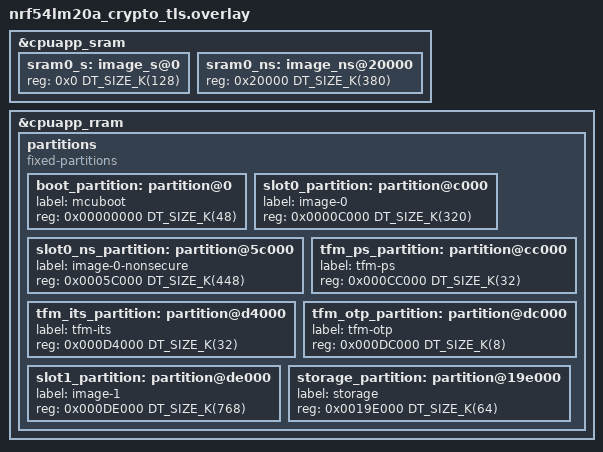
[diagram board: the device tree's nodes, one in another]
/*
 * Copyright (c) 2026 Nordic Semiconductor ASA
 *
 * SPDX-License-Identifier: LicenseRef-Nordic-5-Clause
 */

/*
 * Crypto/TLS-heavy TF-M partition layout for nRF54LM20A
 *
 * nRF54LM20A has 2036 kB of RRAM and 512 kB of SRAM (508 kB usable).
 * TrustZone flash region alignment: 4 kB (MPC-based)
 * TrustZone RAM region alignment:   4 kB
 * RRAM erase-block-size:            4 kB
 *
 * Optimized for TLS/DTLS-heavy applications:
 * - Enlarged PS (32 kB) for X.509 certificate chains
 * - Enlarged ITS (32 kB) for TLS session keys and PSKs
 * - Full TF-M crypto for TLS 1.2/1.3
 * - MCUboot for secure firmware updates
 * - Large NS application space
 *
 * Suitable for: cloud-connected devices, HTTPS clients, MQTT+TLS
 */

&cpuapp_sram {
	sram0_s: image_s@0 {
		#address-cells = <1>;
		#size-cells = <1>;
		reg = <0x0 DT_SIZE_K(128)>;
		ranges = <0x0 0x0 DT_SIZE_K(128)>;
	};

	sram0_ns: image_ns@20000 {
		#address-cells = <1>;
		#size-cells = <1>;
		reg = <0x20000 DT_SIZE_K(380)>;
		ranges = <0x0 0x20000 DT_SIZE_K(380)>;
	};
};

&cpuapp_rram {
	partitions {
		compatible = "fixed-partitions";
		#address-cells = <1>;
		#size-cells = <1>;

		/*
		 * Flash layout (all addresses 4 kB aligned):
		 *
		 * 0x00000000  MCUboot bootloader        (48 kB)
		 * 0x0000C000  Primary slot:
		 *   0x0000C000  TF-M secure image       (320 kB)
		 *   0x0005C000  Non-secure application   (448 kB)
		 * 0x000CC000  TF-M PS                    (32 kB)
		 *             (enlarged for X.509 certificate chains)
		 * 0x000D4000  TF-M ITS                   (32 kB)
		 *             (enlarged for TLS session keys, PSKs)
		 * 0x000DC000  TF-M OTP / NV counters      (8 kB)
		 * 0x000DE000  Secondary slot            (768 kB)
		 * 0x0019E000  Non-secure storage         (64 kB)
		 *
		 * Primary = 320 + 448 = 768 kB = Secondary
		 * Total: 48 + 768 + 32 + 32 + 8 + 768 + 64 = 1720 kB
		 */

		boot_partition: partition@0 {
			label = "mcuboot";
			reg = <0x00000000 DT_SIZE_K(48)>;
		};

		slot0_partition: partition@c000 {
			label = "image-0";
			reg = <0x0000C000 DT_SIZE_K(320)>;
		};

		slot0_ns_partition: partition@5c000 {
			label = "image-0-nonsecure";
			reg = <0x0005C000 DT_SIZE_K(448)>;
		};

		tfm_ps_partition: partition@cc000 {
			label = "tfm-ps";
			reg = <0x000CC000 DT_SIZE_K(32)>;
		};

		tfm_its_partition: partition@d4000 {
			label = "tfm-its";
			reg = <0x000D4000 DT_SIZE_K(32)>;
		};

		tfm_otp_partition: partition@dc000 {
			label = "tfm-otp";
			reg = <0x000DC000 DT_SIZE_K(8)>;
		};

		slot1_partition: partition@de000 {
			label = "image-1";
			reg = <0x000DE000 DT_SIZE_K(768)>;
		};

		storage_partition: partition@19e000 {
			label = "storage";
			reg = <0x0019E000 DT_SIZE_K(64)>;
		};
	};
};
